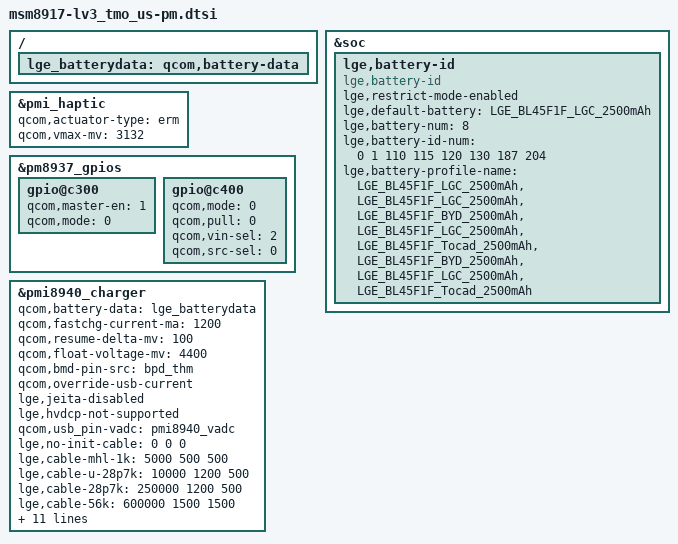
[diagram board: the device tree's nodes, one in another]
/*
 * Copyright (c) 2016, The Linux Foundation. All rights reserved.
 *
 * This program is free software; you can redistribute it and/or modify
 * it under the terms of the GNU General Public License version 2 and
 * only version 2 as published by the Free Software Foundation.
 *
 * This program is distributed in the hope that it will be useful,
 * but WITHOUT ANY WARRANTY; without even the implied warranty of
 * MERCHANTABILITY or FITNESS FOR A PARTICULAR PURPOSE.  See the
 * GNU General Public License for more details.
 */

/{
    lge_batterydata: qcom,battery-data {
         #include "../battery_profile/LGE_BL45F1F_LGC_2500mAh.dtsi"
         #include "../battery_profile/LGE_BL45F1F_Tocad_2500mAh.dtsi"
         #include "../battery_profile/LGE_BL45F1F_BYD_2500mAh.dtsi"
    };
};

&soc {
	lge,battery-id{
		compatible = "lge,battery-id";
		lge,restrict-mode-enabled;
		/*default battery profile*/
		lge,default-battery = "LGE_BL45F1F_LGC_2500mAh";
		/*Total number of combined of battery cell and battery id */
		lge,battery-num = <8>;
		/* battery id and battery profile match numbers */
		lge,battery-id-num = <0 1 110 115 120 130 187 204>;
		/* battery profile */
		lge,battery-profile-name = "LGE_BL45F1F_LGC_2500mAh",
						"LGE_BL45F1F_LGC_2500mAh",
						"LGE_BL45F1F_BYD_2500mAh",
						"LGE_BL45F1F_LGC_2500mAh",
						"LGE_BL45F1F_Tocad_2500mAh",
						"LGE_BL45F1F_BYD_2500mAh",
						"LGE_BL45F1F_LGC_2500mAh",
						"LGE_BL45F1F_Tocad_2500mAh";
	};
};

&pmi_haptic{
	status = "okay";
	qcom,actuator-type = "erm";
	qcom,vmax-mv = <3132>;
};

&pm8937_gpios {
	gpio@c300 {
		qcom,master-en = <1>;
		qcom,mode = <0>;
		status = "okay";
	};

	gpio@c400 {
		qcom,mode = <0>;
		qcom,pull = <0>;
		qcom,vin-sel = <2>;
		qcom,src-sel = <0>;
		status = "okay";
	};
};

&pmi8940_charger {
	qcom,battery-data = <&lge_batterydata>;
	qcom,fastchg-current-ma = <1200>;
	qcom,resume-delta-mv = <100>;
	qcom,float-voltage-mv = <4400>;
	qcom,bmd-pin-src = "bpd_thm";
	qcom,override-usb-current;
	lge,jeita-disabled;
	lge,hvdcp-not-supported;

	qcom,usb_pin-vadc = <&pmi8940_vadc>;

	/* ref resistance 200K */
	lge,no-init-cable = <0 0 0>;
	lge,cable-mhl-1k = <5000 500 500>;
	lge,cable-u-28p7k = <10000 1200 500>;
	lge,cable-28p7k = <250000 1200 500>;
	lge,cable-56k = <600000 1500 1500>;
	lge,cable-100k = <620000 1200 500>;
	lge,cable-130k = <780000 1500 1500>;
	lge,cable-180k = <870000 1200 500>;
	lge,cable-200k = <910000 1200 500>;
	lge,cable-220k = <960000 1200 500>;
	lge,cable-270k = <1050000 1200 500>;
	lge,cable-330k = <1150000 1200 500>;
	lge,cable-620k = <1380000 1200 500>;
	lge,cable-910k = <1630000 1500 1500>;
	lge,cable-none = <1900000 1200  500>;

	lge,usb-max-current-ma = <1200>;
};
